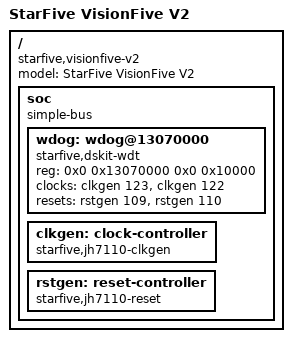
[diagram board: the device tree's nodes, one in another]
/dts-v1/;

/*
 * The watchdog **as radon's own U-Boot describes it** (milestone 593 (a wedged kernel resets
 * itself), provisional). NOT a dump from the board and not a copy of any upstream file. The
 * values below were read from `arch/riscv/dts/jh7110.dtsi` in starfive-tech/u-boot, branch
 * `JH7110_VisionFive2_devel`, at commit c4c67bb66ae6, fetched 2026-11-01 (UTC); that is the tree
 * family radon's boot.scr hands the kernel (crates/machine_discovery/tests/fixtures/
 * jh7110-pmic-bus-radon.dts says how). Only the properties the tests read are kept. Numbers are
 * written out because the vendor headers are not vendored here: JH7110_DSKIT_WDT_CLK_WDT 123,
 * JH7110_DSKIT_WDT_CLK_APB 122, RSTN_U0_DSKIT_WDT_APB 109, RSTN_U0_DSKIT_WDT_CORE 110.
 *
 * What this fixture holds: the vendor binding `starfive,dskit-wdt`, not mainline's; the core clock
 * named before the bus clock; clocks from `clkgen` and resets from the separate `rstgen`. The two
 * provider nodes keep only the `compatible` and cell-count properties the discovery reads; their
 * windows, `status` and the watchdog's own interrupt, `clock-frequency` and `timeout-sec` are left
 * out because no test reads them.
 *
 * Regenerate with:
 *
 *     dtc -I dts -O dtb -o crates/jh7110_watchdog/tests/fixtures/jh7110-watchdog-radon.dtb \
 *                          crates/jh7110_watchdog/tests/fixtures/jh7110-watchdog-radon.dts
 */

/ {
	#address-cells = <2>;
	#size-cells = <2>;
	compatible = "starfive,visionfive-v2", "starfive,jh7110";
	model = "StarFive VisionFive V2";

	soc {
		compatible = "simple-bus";
		#address-cells = <2>;
		#size-cells = <2>;
		ranges;

		wdog: wdog@13070000 {
			compatible = "starfive,dskit-wdt";
			reg = <0x0 0x13070000 0x0 0x10000>;
			clocks = <&clkgen 123>, <&clkgen 122>;
			clock-names = "core_clk", "apb_clk";
			resets = <&rstgen 109>, <&rstgen 110>;
			reset-names = "rst_apb", "rst_core";
		};

		clkgen: clock-controller {
			compatible = "starfive,jh7110-clkgen";
			#clock-cells = <1>;
		};

		rstgen: reset-controller {
			compatible = "starfive,jh7110-reset";
			#reset-cells = <1>;
		};
	};
};
